/*---------GLOBAL DEFINITIONS-----------*/
LIN_description_file;
LIN_protocol_version = "2.1";
LIN_language_version = "2.1";
LIN_speed = 9.6 kbps;
/* ----------NODE DEFINITIONS---------- */
Nodes {
   Master:
      SeatECU, /* Master node name */
      5.0 ms, /* Time base */
      0.1 ms; /* Jitter */
   Slaves:
      Motor1,
      Motor2;
}
/* ----------SIGNAL DEFINITIONS---------- */
Signals {
   /* Signal_name : Size, Init, Publisher, Subscriber(s) */
   Motor1ErrorCode : 8, 0x5, Motor1, SeatECU;
   Motor1ErrorValue : 8, 0x1, Motor1, SeatECU;
   Motor1LinError : 1, 0x0, Motor1, SeatECU;
   Motor1Selection : 2, 0x0, SeatECU, Motor1;
   Motor1Temp : 8, 0x5, Motor1, SeatECU;
   Motor2ErrorCode : 8, 0x2, Motor2, SeatECU;
   Motor2ErrorValue : 8, 0x4, Motor2, SeatECU;
   Motor2LinError : 1, 0x0, Motor2, SeatECU;
   Motor2Selection : 2, 0x0, SeatECU, Motor2;
   Motor2Temp : 8, 0x0, Motor2, SeatECU;
   MotorDirection : 2, 0x0, SeatECU, Motor1,Motor2;
   MotorSpeed : 10, 0x0, SeatECU, Motor1,Motor2;
   Motor1Position : 32, {0x0,0x0,0x0,0x0}, Motor1, SeatECU;
   Motor2Position : 32, {0x0,0x0,0x0,0x0}, Motor2, SeatECU;
}
/* ----------DIAGNOSTIC SIGNAL DEFINITIONS---------- */
Diagnostic_signals {
   /* MasterReq Reserved Signals */
   MasterReqB0 : 8, 0;
   MasterReqB1 : 8, 0;
   MasterReqB2 : 8, 0;
   MasterReqB3 : 8, 0;
   MasterReqB4 : 8, 0;
   MasterReqB5 : 8, 0;
   MasterReqB6 : 8, 0;
   MasterReqB7 : 8, 0;
   /* SlaveResp Reserved Signals */
   SlaveRespB0 : 8, 0;
   SlaveRespB1 : 8, 0;
   SlaveRespB2 : 8, 0;
   SlaveRespB3 : 8, 0;
   SlaveRespB4 : 8, 0;
   SlaveRespB5 : 8, 0;
   SlaveRespB6 : 8, 0;
   SlaveRespB7 : 8, 0;
}
/* ----------UNCONDITIONAL FRAME DEFINITIONS---------- */
Frames {
   Motor1Control : 0x30, SeatECU , 1 {
      Motor1Selection , 0;
   }
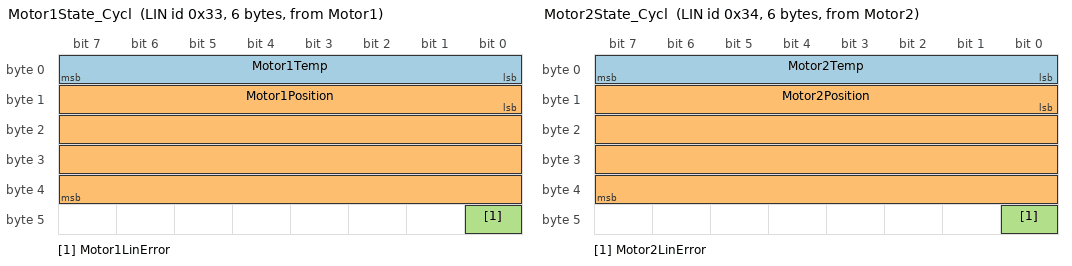
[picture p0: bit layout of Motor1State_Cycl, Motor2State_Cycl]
   Motor1State_Cycl : 0x33, Motor1 , 6 {
      Motor1Temp , 0;
      Motor1Position , 8;
      Motor1LinError , 40;
   }
   Motor1State_Event : 0x36, Motor1 , 3 {
      Motor1ErrorCode , 8;
      Motor1ErrorValue , 16;
   }
   Motor2Control : 0x31, SeatECU , 1 {
      Motor2Selection , 0;
   }
   Motor2State_Cycl : 0x34, Motor2 , 6 {
      Motor2Temp , 0;
      Motor2Position , 8;
      Motor2LinError , 40;
   }
   Motor2State_Event : 0x37, Motor2 , 3 {
      Motor2ErrorCode , 8;
      Motor2ErrorValue , 16;
   }
   MotorsControl : 0x2d, SeatECU , 8 {
      MotorDirection , 0;
      MotorSpeed , 2;
   }
}
/* ----------SPORADIC FRAME DEFINITIONS---------- */
Sporadic_frames {
   SporadicControlFrame: Motor1Control, Motor2Control;
}
/* ----------EVENT TRIGGERD FRAME DEFINITIONS---------- */
Event_triggered_frames {
   ETF_MotorStates : ETFCollisionResolving, 0x3a, Motor1State_Event, Motor2State_Event;
}
/* ----------DIAGNOSTIC FRAME DEFINITIONS---------- */
Diagnostic_frames {
   MasterReq : 0x3c {
      MasterReqB0 , 0;
      MasterReqB1 , 8;
      MasterReqB2 , 16;
      MasterReqB3 , 24;
      MasterReqB4 , 32;
      MasterReqB5 , 40;
      MasterReqB6 , 48;
      MasterReqB7 , 56;
   }
   SlaveResp : 0x3d {
      SlaveRespB0 , 0;
      SlaveRespB1 , 8;
      SlaveRespB2 , 16;
      SlaveRespB3 , 24;
      SlaveRespB4 , 32;
      SlaveRespB5 , 40;
      SlaveRespB6 , 48;
      SlaveRespB7 , 56;
   }
}
/* ----------NODE ATTRIBUTE DEFINITIONS---------- */
Node_attributes {
   Motor1 {
      LIN_protocol = "2.1"; /* Node protocol version */
      configured_NAD = 0x2; /* configured NAD of node (1-125) */
      initial_NAD = 0xa; /* initial NAD of node (1-125) */
      product_id = 0x1e, 0x1, 0x0; /* Product id */
      response_error = Motor1LinError; /* Response error signal */
      fault_state_signals = Motor1ErrorValue, Motor1ErrorCode; /* Fault state signals */
      N_As_timeout = 1000 ms; /* N_As timeout value */
      N_Cr_timeout = 1000 ms; /* N_Cr timeout value */
      configurable_frames {
         MotorsControl;
         Motor1Control;
         Motor1State_Cycl;
         Motor1State_Event;
         ETF_MotorStates;
         SporadicControlFrame;
      }
   }
   Motor2 {
      LIN_protocol = "2.1"; /* Node protocol version */
      configured_NAD = 0x3; /* configured NAD of node (1-125) */
      initial_NAD = 0xc; /* initial NAD of node (1-125) */
      product_id = 0x2e, 0xb, 0x1; /* Product id */
      response_error = Motor2LinError; /* Response error signal */
      fault_state_signals = Motor2ErrorValue, Motor2ErrorCode; /* Fault state signals */
      N_As_timeout = 1000 ms; /* N_As timeout value */
      N_Cr_timeout = 1000 ms; /* N_Cr timeout value */
      configurable_frames {
         MotorsControl;
         Motor2Control;
         Motor2State_Cycl;
         Motor2State_Event;
         ETF_MotorStates;
         SporadicControlFrame;
      }
   }
}
/* ----------SCHEDULE TABLE DEFINITIONS---------- */
Schedule_tables {
   NormalTable {
      Motor1Control delay 50.0 ms;
      Motor1State_Cycl delay 50.0 ms;
   }
   ETFCollisionResolving {
      Motor1State_Event delay 50.0 ms;
      Motor2State_Event delay 50.0 ms;
      MotorsControl delay 60.0 ms;
      Motor1State_Cycl delay 50.0 ms;
      Motor2State_Cycl delay 50.0 ms;
      SporadicControlFrame delay 50.0 ms;
   }
   InitTable {
      AssignNAD {Motor1} delay 50.0 ms;
      SlaveResp delay 50.0 ms;
      AssignNAD {Motor2} delay 50.0 ms;
      SlaveResp delay 50.0 ms;
      AssignFrameIdRange {Motor1, 0} delay 50.0 ms;
      AssignFrameIdRange {Motor1, 4} delay 50.0 ms;
      AssignFrameIdRange {Motor2, 0} delay 50.0 ms;
      AssignFrameIdRange {Motor2, 4} delay 50.0 ms;
   }
}
